# nrf7120E_enga_application register map
Vendor: Nordic Semiconductor; Series: nrf71; File version: 1
CPU: CM33 r0p4, little endian, MPU, FPU, 3 interrupt priority bits, 270 interrupts, 4 SAU regions
Registers are 32-bit, read-write, reset 0x0 unless marked. A register's access mark holds for its fields unless they carry their own. Offsets are from the block's base; [hi:lo] are bit positions; 'fields as' and 'values as' point back to an identical list.

## GLOBAL_LFXO_NS — LFXO peripheral 0
Base 0x40122000
Same registers: GLOBAL_LFXO_S 0x50122000
0x100 EVENTS_MODECHANGED — LFXO mode changed
  [0] EVENTS_MODECHANGED
    0=NotGenerated (Event not generated); 1=Generated (Event generated)
0x104 EVENTS_ERRORSTARTING — Error while starting the LFXO in PIERCE mode
  [0] EVENTS_ERRORSTARTING
    values as EVENTS_MODECHANGED.EVENTS_MODECHANGED
0x108 EVENTS_ERRORRUNNING — Error detected while LFXO was running
  [0] EVENTS_ERRORRUNNING
    values as EVENTS_MODECHANGED.EVENTS_MODECHANGED
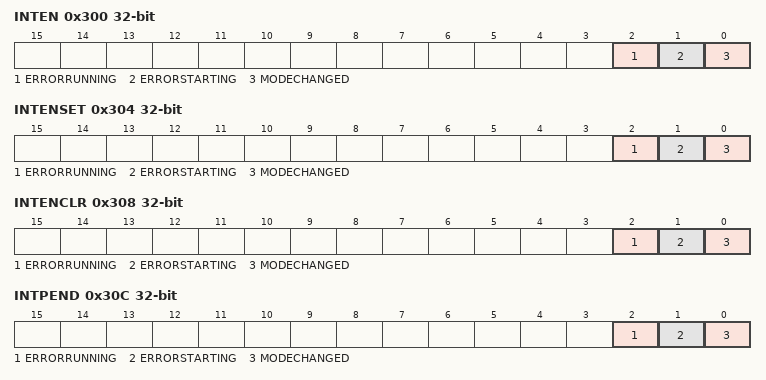
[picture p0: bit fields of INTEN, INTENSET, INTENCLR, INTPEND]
0x300 INTEN — Enable or disable interrupt
  [all] fields
    0=Disabled; 1=Enabled
  [2] ERRORRUNNING — Enable or disable interrupt for event ERRORRUNNING
  [1] ERRORSTARTING — Enable or disable interrupt for event ERRORSTARTING
  [0] MODECHANGED — Enable or disable interrupt for event MODECHANGED
0x304 INTENSET — Enable interrupt
  [all] fields
    on read: 0=Disabled (Read: Disabled); 1=Enabled (Read: Enabled) | on write: 1=Set (Enable)
  [2] ERRORRUNNING write-1-sets — Write '1' to enable interrupt for event ERRORRUNNING
  [1] ERRORSTARTING write-1-sets — Write '1' to enable interrupt for event ERRORSTARTING
  [0] MODECHANGED write-1-sets — Write '1' to enable interrupt for event MODECHANGED
0x308 INTENCLR — Disable interrupt
  [all] fields
    on read: 0=Disabled (Read: Disabled); 1=Enabled (Read: Enabled) | on write: 1=Clear (Disable)
  [2] ERRORRUNNING write-1-clears — Write '1' to disable interrupt for event ERRORRUNNING
  [1] ERRORSTARTING write-1-clears — Write '1' to disable interrupt for event ERRORSTARTING
  [0] MODECHANGED write-1-clears — Write '1' to disable interrupt for event MODECHANGED
0x30C INTPEND ro — Pending interrupts
  [all] fields
    on read: 0=NotPending (Read: Not pending); 1=Pending (Read: Pending)
  [2] ERRORRUNNING — Read pending status of interrupt for event ERRORRUNNING
  [1] ERRORSTARTING — Read pending status of interrupt for event ERRORSTARTING
  [0] MODECHANGED — Read pending status of interrupt for event MODECHANGED
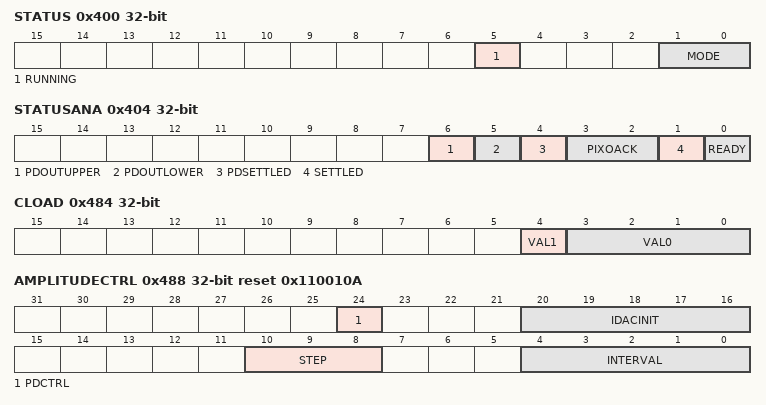
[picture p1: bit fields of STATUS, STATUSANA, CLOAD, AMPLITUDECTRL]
0x400 STATUS ro — LFXO status
  [5] RUNNING — LFXO running status
    0=NotRunning (LFXO not running); 1=Running (LFXO running)
  [1:0] MODE — Current mode
    0=Pierce mode; 1=PIXO mode
0x404 STATUSANA ro — Status of analog module output signals
  [6] PDOUTUPPER — Current value of the PD_OUT_UPPER signal from the analog module
  [5] PDOUTLOWER — Current value of the PD_OUT_LOWER signal from the analog module
  [4] PDSETTLED — Current value of the PD_SETTLED signal from the analog module
  [3:2] PIXOACK — Current value of the PIXO_ACK signal from the analog module
  [1] SETTLED — Current value of the SETTLED signal from the analog module
  [0] READY — Current value of the READY signal from the analog module
0x480 MIRROR reset 0x1 — Enable LOCK for mirrored registers
  [0] LOCK — Lock for mirrored registers
    0=Disabled (Lock disabled); 1=Enabled (Lock enabled)
0x484 CLOAD — Internal capacitive load
  [4] VAL1 — Capacitive load value
  [3:0] VAL0 — Capacitive load value
0x488 AMPLITUDECTRL reset 0x110010A — Amplitude control
  [24] PDCTRL — Peak detector control
    0=Disabled (Peak detector disabled); 1=Enabled (Peak detector enabled)
  [20:16] IDACINIT — Initial IDAC code for the pierce oscillator
  [10:8] STEP — Step to adjust the IDAC when the peak detector triggers
  [4:0] INTERVAL — Amplitude check interval
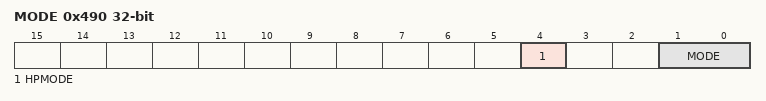
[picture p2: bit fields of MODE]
0x490 MODE — LFXO mode
  [4] HPMODE — High performance mode
    0=Disabled (Disable high performance mode); 1=Enabled (Enable high performance mode)
  [1:0] MODE
    0=Pierce mode; 1=PIXO mode

## GLOBAL_HFXO64M_NS — HFXO64M peripheral 0
Base 0x40124000
Same registers: GLOBAL_HFXO64M_S 0x50124000
0x100 EVENTS_STARTED — HFXO64M started
  [0] EVENTS_STARTED
    0=NotGenerated (Event not generated); 1=Generated (Event generated)
0x104 EVENTS_STOPPED — HFXO64M stopped
  [0] EVENTS_STOPPED
    values as EVENTS_STARTED.EVENTS_STARTED
0x108 EVENTS_ERRORBIAS — Error with BIAS setup
  [0] EVENTS_ERRORBIAS
    values as EVENTS_STARTED.EVENTS_STARTED
0x10C EVENTS_ERRORDETECTOR — Error with DETECTOR
  [0] EVENTS_ERRORDETECTOR
    values as EVENTS_STARTED.EVENTS_STARTED
0x110 EVENTS_ERRORTCXO — Error with TCXO startup
  [0] EVENTS_ERRORTCXO
    values as EVENTS_STARTED.EVENTS_STARTED
0x114 EVENTS_STARTREQ — Clock start has been requested
  [0] EVENTS_STARTREQ
    values as EVENTS_STARTED.EVENTS_STARTED
0x118 EVENTS_STOPREQ — Clock stop has been requested
  [0] EVENTS_STOPREQ
    values as EVENTS_STARTED.EVENTS_STARTED
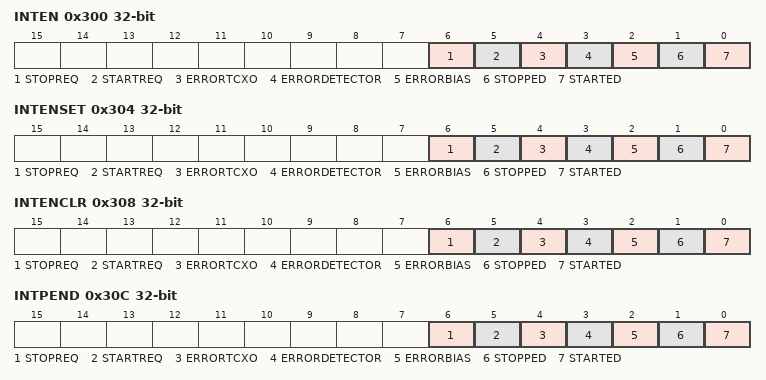
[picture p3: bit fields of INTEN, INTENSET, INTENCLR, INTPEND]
0x300 INTEN — Enable or disable interrupt
  [all] fields
    0=Disabled; 1=Enabled
  [6] STOPREQ — Enable or disable interrupt for event STOPREQ
  [5] STARTREQ — Enable or disable interrupt for event STARTREQ
  [4] ERRORTCXO — Enable or disable interrupt for event ERRORTCXO
  [3] ERRORDETECTOR — Enable or disable interrupt for event ERRORDETECTOR
  [2] ERRORBIAS — Enable or disable interrupt for event ERRORBIAS
  [1] STOPPED — Enable or disable interrupt for event STOPPED
  [0] STARTED — Enable or disable interrupt for event STARTED
0x304 INTENSET — Enable interrupt
  [all] fields
    on read: 0=Disabled (Read: Disabled); 1=Enabled (Read: Enabled) | on write: 1=Set (Enable)
  [6] STOPREQ write-1-sets — Write '1' to enable interrupt for event STOPREQ
  [5] STARTREQ write-1-sets — Write '1' to enable interrupt for event STARTREQ
  [4] ERRORTCXO write-1-sets — Write '1' to enable interrupt for event ERRORTCXO
  [3] ERRORDETECTOR write-1-sets — Write '1' to enable interrupt for event ERRORDETECTOR
  [2] ERRORBIAS write-1-sets — Write '1' to enable interrupt for event ERRORBIAS
  [1] STOPPED write-1-sets — Write '1' to enable interrupt for event STOPPED
  [0] STARTED write-1-sets — Write '1' to enable interrupt for event STARTED
0x308 INTENCLR — Disable interrupt
  [all] fields
    on read: 0=Disabled (Read: Disabled); 1=Enabled (Read: Enabled) | on write: 1=Clear (Disable)
  [6] STOPREQ write-1-clears — Write '1' to disable interrupt for event STOPREQ
  [5] STARTREQ write-1-clears — Write '1' to disable interrupt for event STARTREQ
  [4] ERRORTCXO write-1-clears — Write '1' to disable interrupt for event ERRORTCXO
  [3] ERRORDETECTOR write-1-clears — Write '1' to disable interrupt for event ERRORDETECTOR
  [2] ERRORBIAS write-1-clears — Write '1' to disable interrupt for event ERRORBIAS
  [1] STOPPED write-1-clears — Write '1' to disable interrupt for event STOPPED
  [0] STARTED write-1-clears — Write '1' to disable interrupt for event STARTED
0x30C INTPEND ro — Pending interrupts
  [all] fields
    on read: 0=NotPending (Read: Not pending); 1=Pending (Read: Pending)
  [6] STOPREQ — Read pending status of interrupt for event STOPREQ
  [5] STARTREQ — Read pending status of interrupt for event STARTREQ
  [4] ERRORTCXO — Read pending status of interrupt for event ERRORTCXO
  [3] ERRORDETECTOR — Read pending status of interrupt for event ERRORDETECTOR
  [2] ERRORBIAS — Read pending status of interrupt for event ERRORBIAS
  [1] STOPPED — Read pending status of interrupt for event STOPPED
  [0] STARTED — Read pending status of interrupt for event STARTED

## GLOBAL_OSCRFR_NS — OSCRFR peripheral 0
Base 0x4012A000
Same registers: GLOBAL_OSCRFR_S 0x5012A000

## GLOBAL_AUXPM_NS — AUXPM 0
Base 0x40130000; alternate view of GLOBAL_AUXPLL_NS
Same registers: GLOBAL_AUXPM_S 0x50130000 (alternate view of GLOBAL_AUXPLL_S)
